VERSION ""

NS_ :

BS_:

BU_: HETC_L_ARM HMDO_1 HMAS_11 HMDO_2 HMAS_12 HMDO_3 HMAS_13 HMDO_4 HMAS_14 HMDI_5 HMAS_15

BO_ 2163243263 CTRL_HETC_L_ARM_to_ALL: 7 HETC_L_ARM
 SG_ SubCode M : 0|8@1+ (1,0) [0|0] "" HMDO_1,HMAS_11,HMDO_2,HMAS_12,HMDO_3,HMAS_13,HMDO_4,HMAS_14,HMDI_5,HMAS_15
 SG_ Rtc_Year2000 m9 : 8|8@1+ (1,0) [0|0] "" HMDO_1,HMAS_11,HMDO_2,HMAS_12,HMDO_3,HMAS_13,HMDO_4,HMAS_14,HMDI_5,HMAS_15
 SG_ Rtc_Month m9 : 16|8@1+ (1,0) [0|0] "" HMDO_1,HMAS_11,HMDO_2,HMAS_12,HMDO_3,HMAS_13,HMDO_4,HMAS_14,HMDI_5,HMAS_15
 SG_ Rtc_Day m9 : 24|8@1+ (1,0) [0|0] "" HMDO_1,HMAS_11,HMDO_2,HMAS_12,HMDO_3,HMAS_13,HMDO_4,HMAS_14,HMDI_5,HMAS_15
 SG_ Rtc_Hour m9 : 32|8@1+ (1,0) [0|0] "" HMDO_1,HMAS_11,HMDO_2,HMAS_12,HMDO_3,HMAS_13,HMDO_4,HMAS_14,HMDI_5,HMAS_15
 SG_ Rtc_Min m9 : 40|8@1+ (1,0) [0|0] "" HMDO_1,HMAS_11,HMDO_2,HMAS_12,HMDO_3,HMAS_13,HMDO_4,HMAS_14,HMDI_5,HMAS_15
 SG_ Rtc_Sec m9 : 48|8@1+ (1,0) [0|0] "" HMDO_1,HMAS_11,HMDO_2,HMAS_12,HMDO_3,HMAS_13,HMDO_4,HMAS_14,HMDI_5,HMAS_15

BO_ 2163374335 QUIET_HETC_L_ARM_to_ALL: 6 HETC_L_ARM
 SG_ Divider : 0|16@1+ (1,0) [0|0] "" HMDO_1,HMAS_11,HMDO_2,HMAS_12,HMDO_3,HMAS_13,HMDO_4,HMAS_14,HMDI_5,HMAS_15
 SG_ HoldMs : 16|32@1+ (1,0) [0|0] "ms" HMDO_1,HMAS_11,HMDO_2,HMAS_12,HMDO_3,HMAS_13,HMDO_4,HMAS_14,HMDI_5,HMAS_15

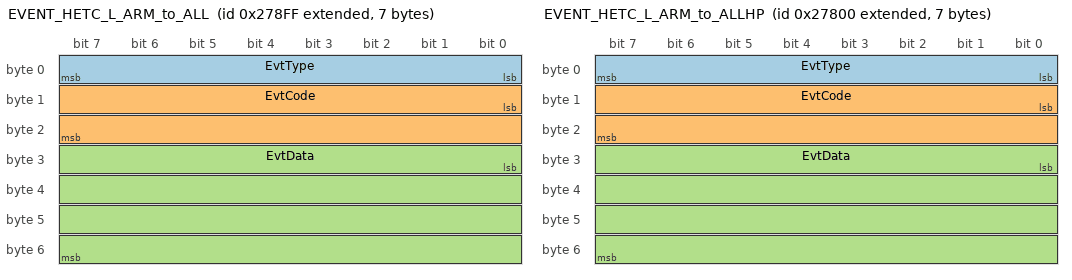
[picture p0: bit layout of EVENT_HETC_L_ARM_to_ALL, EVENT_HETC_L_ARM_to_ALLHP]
BO_ 2147645695 EVENT_HETC_L_ARM_to_ALL: 7 HETC_L_ARM
 SG_ EvtType : 0|8@1+ (1,0) [0|0] "" HMDO_1,HMAS_11,HMDO_2,HMAS_12,HMDO_3,HMAS_13,HMDO_4,HMAS_14,HMDI_5,HMAS_15
 SG_ EvtCode : 8|16@1+ (1,0) [0|0] "" HMDO_1,HMAS_11,HMDO_2,HMAS_12,HMDO_3,HMAS_13,HMDO_4,HMAS_14,HMDI_5,HMAS_15
 SG_ EvtData : 24|32@1+ (1,0) [0|0] "" HMDO_1,HMAS_11,HMDO_2,HMAS_12,HMDO_3,HMAS_13,HMDO_4,HMAS_14,HMDI_5,HMAS_15

BO_ 2147645440 EVENT_HETC_L_ARM_to_ALLHP: 7 HETC_L_ARM
 SG_ EvtType : 0|8@1+ (1,0) [0|0] "" HMDO_1,HMAS_11,HMDO_2,HMAS_12,HMDO_3,HMAS_13,HMDO_4,HMAS_14,HMDI_5,HMAS_15
 SG_ EvtCode : 8|16@1+ (1,0) [0|0] "" HMDO_1,HMAS_11,HMDO_2,HMAS_12,HMDO_3,HMAS_13,HMDO_4,HMAS_14,HMDI_5,HMAS_15
 SG_ EvtData : 24|32@1+ (1,0) [0|0] "" HMDO_1,HMAS_11,HMDO_2,HMAS_12,HMDO_3,HMAS_13,HMDO_4,HMAS_14,HMDI_5,HMAS_15

BO_ 2147710977 RPDO_HETC_L_ARM_to_HMDO_1: 16 HETC_L_ARM
 SG_ Type : 0|8@1+ (1,0) [0|0] "" HMDO_1
 SG_ ReqState : 8|8@1+ (1,0) [0|0] "" HMDO_1
 SG_ DesiredMode : 16|8@1+ (1,0) [0|0] "" HMDO_1
 SG_ DesiredPosition : 24|32@1- (1,0) [0|0] "rad" HMDO_1
 SG_ DesiredVelocity : 56|32@1- (1,0) [0|0] "rad/s" HMDO_1
 SG_ DesiredTorque : 88|32@1- (1,0) [0|0] "" HMDO_1

BO_ 2147746168 TPDO_HMDO_1_to_HETC_L_ARM: 20 HMDO_1
 SG_ Type : 0|8@1+ (1,0) [0|0] "" HETC_L_ARM
 SG_ ErrCode : 8|32@1+ (1,0) [0|0] "" HETC_L_ARM
 SG_ PresentState : 40|8@1+ (1,0) [0|0] "" HETC_L_ARM
 SG_ PresentMode : 48|8@1+ (1,0) [0|0] "" HETC_L_ARM
 SG_ PresentPosition : 56|32@1- (1,0) [0|0] "rad" HETC_L_ARM
 SG_ PresentVelocity : 88|32@1- (1,0) [0|0] "rad/s" HETC_L_ARM
 SG_ PresentTorque : 120|32@1- (1,0) [0|0] "" HETC_L_ARM
 SG_ Temperature : 152|8@1- (1,0) [0|0] "degC" HETC_L_ARM

BO_ 2163278200 STATUS_HMDO_1_to_HETC_L_ARM: 48 HMDO_1
 SG_ SubCode M : 0|8@1+ (1,0) [0|0] "" HETC_L_ARM
 SG_ Ping_CanId m5 : 8|8@1+ (1,0) [0|0] "" HETC_L_ARM
 SG_ Ping_HostId m5 : 16|8@1+ (1,0) [0|0] "" HETC_L_ARM
 SG_ Ping_Pid m5 : 24|16@1+ (1,0) [0|0] "" HETC_L_ARM
 SG_ Ping_Bid m5 : 40|16@1+ (1,0) [0|0] "" HETC_L_ARM
 SG_ Ping_Mid m5 : 56|16@1+ (1,0) [0|0] "" HETC_L_ARM
 SG_ Ping_VerMajor m5 : 72|8@1+ (1,0) [0|0] "" HETC_L_ARM
 SG_ Ping_VerMinor m5 : 80|8@1+ (1,0) [0|0] "" HETC_L_ARM
 SG_ Ping_VerPatch m5 : 88|8@1+ (1,0) [0|0] "" HETC_L_ARM
 SG_ Ping_Name0 m5 : 96|8@1+ (1,0) [0|0] "" HETC_L_ARM
 SG_ Ping_Name1 m5 : 104|8@1+ (1,0) [0|0] "" HETC_L_ARM
 SG_ Ping_Name2 m5 : 112|8@1+ (1,0) [0|0] "" HETC_L_ARM
 SG_ Ping_Name3 m5 : 120|8@1+ (1,0) [0|0] "" HETC_L_ARM
 SG_ Ping_Name4 m5 : 128|8@1+ (1,0) [0|0] "" HETC_L_ARM
 SG_ Ping_Name5 m5 : 136|8@1+ (1,0) [0|0] "" HETC_L_ARM
 SG_ Ping_Name6 m5 : 144|8@1+ (1,0) [0|0] "" HETC_L_ARM
 SG_ Ping_Name7 m5 : 152|8@1+ (1,0) [0|0] "" HETC_L_ARM
 SG_ Ping_Name8 m5 : 160|8@1+ (1,0) [0|0] "" HETC_L_ARM
 SG_ Ping_Name9 m5 : 168|8@1+ (1,0) [0|0] "" HETC_L_ARM
 SG_ Ping_Name10 m5 : 176|8@1+ (1,0) [0|0] "" HETC_L_ARM
 SG_ Ping_Name11 m5 : 184|8@1+ (1,0) [0|0] "" HETC_L_ARM
 SG_ Ping_Name12 m5 : 192|8@1+ (1,0) [0|0] "" HETC_L_ARM
 SG_ Ping_Name13 m5 : 200|8@1+ (1,0) [0|0] "" HETC_L_ARM
 SG_ Ping_Name14 m5 : 208|8@1+ (1,0) [0|0] "" HETC_L_ARM
 SG_ Ping_Name15 m5 : 216|8@1+ (1,0) [0|0] "" HETC_L_ARM
 SG_ Ping_FmtVer m5 : 224|8@1+ (1,0) [0|0] "" HETC_L_ARM
 SG_ Ping_GitRev m5 : 232|32@1+ (1,0) [0|0] "" HETC_L_ARM
 SG_ Ping_FwCrc m5 : 264|16@1+ (1,0) [0|0] "" HETC_L_ARM
 SG_ Ping_UptimeS m5 : 280|16@1+ (1,0) [0|0] "s" HETC_L_ARM

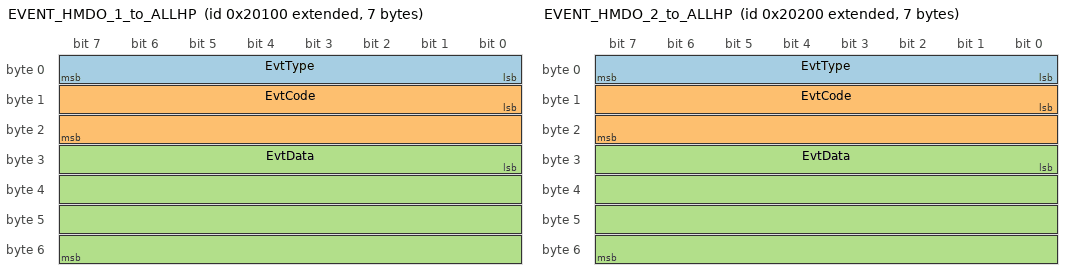
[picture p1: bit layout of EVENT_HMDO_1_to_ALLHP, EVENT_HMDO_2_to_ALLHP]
BO_ 2147614976 EVENT_HMDO_1_to_ALLHP: 7 HMDO_1
 SG_ EvtType : 0|8@1+ (1,0) [0|0] "" HETC_L_ARM,HMAS_11,HMDO_2,HMAS_12,HMDO_3,HMAS_13,HMDO_4,HMAS_14,HMDI_5,HMAS_15
 SG_ EvtCode : 8|16@1+ (1,0) [0|0] "" HETC_L_ARM,HMAS_11,HMDO_2,HMAS_12,HMDO_3,HMAS_13,HMDO_4,HMAS_14,HMDI_5,HMAS_15
 SG_ EvtData : 24|32@1+ (1,0) [0|0] "" HETC_L_ARM,HMAS_11,HMDO_2,HMAS_12,HMDO_3,HMAS_13,HMDO_4,HMAS_14,HMDI_5,HMAS_15

BO_ 2163280641 STATUS_HMAS_11_to_HMDO_1: 7 HMAS_11
 SG_ SubCode M : 0|8@1+ (1,0) [0|0] "" HMDO_1
 SG_ Ang_Ready m17 : 8|1@1+ (1,0) [0|0] "" HMDO_1
 SG_ Ang_Valid m17 : 9|1@1+ (1,0) [0|0] "" HMDO_1
 SG_ Ang_ExtErr m17 : 12|8@1+ (1,0) [0|0] "" HMDO_1
 SG_ Ang_AngleRad m17 : 24|32@1- (1,0) [0|0] "rad" HMDO_1

BO_ 2163280760 STATUS_HMAS_11_to_HETC_L_ARM: 48 HMAS_11
 SG_ SubCode M : 0|8@1+ (1,0) [0|0] "" HETC_L_ARM
 SG_ Ping_CanId m5 : 8|8@1+ (1,0) [0|0] "" HETC_L_ARM
 SG_ Ping_HostId m5 : 16|8@1+ (1,0) [0|0] "" HETC_L_ARM
 SG_ Ping_Pid m5 : 24|16@1+ (1,0) [0|0] "" HETC_L_ARM
 SG_ Ping_Bid m5 : 40|16@1+ (1,0) [0|0] "" HETC_L_ARM
 SG_ Ping_Mid m5 : 56|16@1+ (1,0) [0|0] "" HETC_L_ARM
 SG_ Ping_VerMajor m5 : 72|8@1+ (1,0) [0|0] "" HETC_L_ARM
 SG_ Ping_VerMinor m5 : 80|8@1+ (1,0) [0|0] "" HETC_L_ARM
 SG_ Ping_VerPatch m5 : 88|8@1+ (1,0) [0|0] "" HETC_L_ARM
 SG_ Ping_Name0 m5 : 96|8@1+ (1,0) [0|0] "" HETC_L_ARM
 SG_ Ping_Name1 m5 : 104|8@1+ (1,0) [0|0] "" HETC_L_ARM
 SG_ Ping_Name2 m5 : 112|8@1+ (1,0) [0|0] "" HETC_L_ARM
 SG_ Ping_Name3 m5 : 120|8@1+ (1,0) [0|0] "" HETC_L_ARM
 SG_ Ping_Name4 m5 : 128|8@1+ (1,0) [0|0] "" HETC_L_ARM
 SG_ Ping_Name5 m5 : 136|8@1+ (1,0) [0|0] "" HETC_L_ARM
 SG_ Ping_Name6 m5 : 144|8@1+ (1,0) [0|0] "" HETC_L_ARM
 SG_ Ping_Name7 m5 : 152|8@1+ (1,0) [0|0] "" HETC_L_ARM
 SG_ Ping_Name8 m5 : 160|8@1+ (1,0) [0|0] "" HETC_L_ARM
 SG_ Ping_Name9 m5 : 168|8@1+ (1,0) [0|0] "" HETC_L_ARM
 SG_ Ping_Name10 m5 : 176|8@1+ (1,0) [0|0] "" HETC_L_ARM
 SG_ Ping_Name11 m5 : 184|8@1+ (1,0) [0|0] "" HETC_L_ARM
 SG_ Ping_Name12 m5 : 192|8@1+ (1,0) [0|0] "" HETC_L_ARM
 SG_ Ping_Name13 m5 : 200|8@1+ (1,0) [0|0] "" HETC_L_ARM
 SG_ Ping_Name14 m5 : 208|8@1+ (1,0) [0|0] "" HETC_L_ARM
 SG_ Ping_Name15 m5 : 216|8@1+ (1,0) [0|0] "" HETC_L_ARM
 SG_ Ping_FmtVer m5 : 224|8@1+ (1,0) [0|0] "" HETC_L_ARM
 SG_ Ping_GitRev m5 : 232|32@1+ (1,0) [0|0] "" HETC_L_ARM
 SG_ Ping_FwCrc m5 : 264|16@1+ (1,0) [0|0] "" HETC_L_ARM
 SG_ Ping_UptimeS m5 : 280|16@1+ (1,0) [0|0] "s" HETC_L_ARM

BO_ 2147710978 RPDO_HETC_L_ARM_to_HMDO_2: 16 HETC_L_ARM
 SG_ Type : 0|8@1+ (1,0) [0|0] "" HMDO_2
 SG_ ReqState : 8|8@1+ (1,0) [0|0] "" HMDO_2
 SG_ DesiredMode : 16|8@1+ (1,0) [0|0] "" HMDO_2
 SG_ DesiredPosition : 24|32@1- (1,0) [0|0] "rad" HMDO_2
 SG_ DesiredVelocity : 56|32@1- (1,0) [0|0] "rad/s" HMDO_2
 SG_ DesiredTorque : 88|32@1- (1,0) [0|0] "" HMDO_2

BO_ 2147746424 TPDO_HMDO_2_to_HETC_L_ARM: 20 HMDO_2
 SG_ Type : 0|8@1+ (1,0) [0|0] "" HETC_L_ARM
 SG_ ErrCode : 8|32@1+ (1,0) [0|0] "" HETC_L_ARM
 SG_ PresentState : 40|8@1+ (1,0) [0|0] "" HETC_L_ARM
 SG_ PresentMode : 48|8@1+ (1,0) [0|0] "" HETC_L_ARM
 SG_ PresentPosition : 56|32@1- (1,0) [0|0] "rad" HETC_L_ARM
 SG_ PresentVelocity : 88|32@1- (1,0) [0|0] "rad/s" HETC_L_ARM
 SG_ PresentTorque : 120|32@1- (1,0) [0|0] "" HETC_L_ARM
 SG_ Temperature : 152|8@1- (1,0) [0|0] "degC" HETC_L_ARM

BO_ 2163278456 STATUS_HMDO_2_to_HETC_L_ARM: 48 HMDO_2
 SG_ SubCode M : 0|8@1+ (1,0) [0|0] "" HETC_L_ARM
 SG_ Ping_CanId m5 : 8|8@1+ (1,0) [0|0] "" HETC_L_ARM
 SG_ Ping_HostId m5 : 16|8@1+ (1,0) [0|0] "" HETC_L_ARM
 SG_ Ping_Pid m5 : 24|16@1+ (1,0) [0|0] "" HETC_L_ARM
 SG_ Ping_Bid m5 : 40|16@1+ (1,0) [0|0] "" HETC_L_ARM
 SG_ Ping_Mid m5 : 56|16@1+ (1,0) [0|0] "" HETC_L_ARM
 SG_ Ping_VerMajor m5 : 72|8@1+ (1,0) [0|0] "" HETC_L_ARM
 SG_ Ping_VerMinor m5 : 80|8@1+ (1,0) [0|0] "" HETC_L_ARM
 SG_ Ping_VerPatch m5 : 88|8@1+ (1,0) [0|0] "" HETC_L_ARM
 SG_ Ping_Name0 m5 : 96|8@1+ (1,0) [0|0] "" HETC_L_ARM
 SG_ Ping_Name1 m5 : 104|8@1+ (1,0) [0|0] "" HETC_L_ARM
 SG_ Ping_Name2 m5 : 112|8@1+ (1,0) [0|0] "" HETC_L_ARM
 SG_ Ping_Name3 m5 : 120|8@1+ (1,0) [0|0] "" HETC_L_ARM
 SG_ Ping_Name4 m5 : 128|8@1+ (1,0) [0|0] "" HETC_L_ARM
 SG_ Ping_Name5 m5 : 136|8@1+ (1,0) [0|0] "" HETC_L_ARM
 SG_ Ping_Name6 m5 : 144|8@1+ (1,0) [0|0] "" HETC_L_ARM
 SG_ Ping_Name7 m5 : 152|8@1+ (1,0) [0|0] "" HETC_L_ARM
 SG_ Ping_Name8 m5 : 160|8@1+ (1,0) [0|0] "" HETC_L_ARM
 SG_ Ping_Name9 m5 : 168|8@1+ (1,0) [0|0] "" HETC_L_ARM
 SG_ Ping_Name10 m5 : 176|8@1+ (1,0) [0|0] "" HETC_L_ARM
 SG_ Ping_Name11 m5 : 184|8@1+ (1,0) [0|0] "" HETC_L_ARM
 SG_ Ping_Name12 m5 : 192|8@1+ (1,0) [0|0] "" HETC_L_ARM
 SG_ Ping_Name13 m5 : 200|8@1+ (1,0) [0|0] "" HETC_L_ARM
 SG_ Ping_Name14 m5 : 208|8@1+ (1,0) [0|0] "" HETC_L_ARM
 SG_ Ping_Name15 m5 : 216|8@1+ (1,0) [0|0] "" HETC_L_ARM
 SG_ Ping_FmtVer m5 : 224|8@1+ (1,0) [0|0] "" HETC_L_ARM
 SG_ Ping_GitRev m5 : 232|32@1+ (1,0) [0|0] "" HETC_L_ARM
 SG_ Ping_FwCrc m5 : 264|16@1+ (1,0) [0|0] "" HETC_L_ARM
 SG_ Ping_UptimeS m5 : 280|16@1+ (1,0) [0|0] "s" HETC_L_ARM

BO_ 2147615232 EVENT_HMDO_2_to_ALLHP: 7 HMDO_2
 SG_ EvtType : 0|8@1+ (1,0) [0|0] "" HETC_L_ARM,HMDO_1,HMAS_11,HMAS_12,HMDO_3,HMAS_13,HMDO_4,HMAS_14,HMDI_5,HMAS_15
 SG_ EvtCode : 8|16@1+ (1,0) [0|0] "" HETC_L_ARM,HMDO_1,HMAS_11,HMAS_12,HMDO_3,HMAS_13,HMDO_4,HMAS_14,HMDI_5,HMAS_15
 SG_ EvtData : 24|32@1+ (1,0) [0|0] "" HETC_L_ARM,HMDO_1,HMAS_11,HMAS_12,HMDO_3,HMAS_13,HMDO_4,HMAS_14,HMDI_5,HMAS_15

BO_ 2163280898 STATUS_HMAS_12_to_HMDO_2: 7 HMAS_12
 SG_ SubCode M : 0|8@1+ (1,0) [0|0] "" HMDO_2
 SG_ Ang_Ready m17 : 8|1@1+ (1,0) [0|0] "" HMDO_2
 SG_ Ang_Valid m17 : 9|1@1+ (1,0) [0|0] "" HMDO_2
 SG_ Ang_ExtErr m17 : 12|8@1+ (1,0) [0|0] "" HMDO_2
 SG_ Ang_AngleRad m17 : 24|32@1- (1,0) [0|0] "rad" HMDO_2

BO_ 2163281016 STATUS_HMAS_12_to_HETC_L_ARM: 48 HMAS_12
 SG_ SubCode M : 0|8@1+ (1,0) [0|0] "" HETC_L_ARM
 SG_ Ping_CanId m5 : 8|8@1+ (1,0) [0|0] "" HETC_L_ARM
 SG_ Ping_HostId m5 : 16|8@1+ (1,0) [0|0] "" HETC_L_ARM
 SG_ Ping_Pid m5 : 24|16@1+ (1,0) [0|0] "" HETC_L_ARM
 SG_ Ping_Bid m5 : 40|16@1+ (1,0) [0|0] "" HETC_L_ARM
 SG_ Ping_Mid m5 : 56|16@1+ (1,0) [0|0] "" HETC_L_ARM
 SG_ Ping_VerMajor m5 : 72|8@1+ (1,0) [0|0] "" HETC_L_ARM
 SG_ Ping_VerMinor m5 : 80|8@1+ (1,0) [0|0] "" HETC_L_ARM
 SG_ Ping_VerPatch m5 : 88|8@1+ (1,0) [0|0] "" HETC_L_ARM
 SG_ Ping_Name0 m5 : 96|8@1+ (1,0) [0|0] "" HETC_L_ARM
 SG_ Ping_Name1 m5 : 104|8@1+ (1,0) [0|0] "" HETC_L_ARM
 SG_ Ping_Name2 m5 : 112|8@1+ (1,0) [0|0] "" HETC_L_ARM
 SG_ Ping_Name3 m5 : 120|8@1+ (1,0) [0|0] "" HETC_L_ARM
 SG_ Ping_Name4 m5 : 128|8@1+ (1,0) [0|0] "" HETC_L_ARM
 SG_ Ping_Name5 m5 : 136|8@1+ (1,0) [0|0] "" HETC_L_ARM
 SG_ Ping_Name6 m5 : 144|8@1+ (1,0) [0|0] "" HETC_L_ARM
 SG_ Ping_Name7 m5 : 152|8@1+ (1,0) [0|0] "" HETC_L_ARM
 SG_ Ping_Name8 m5 : 160|8@1+ (1,0) [0|0] "" HETC_L_ARM
 SG_ Ping_Name9 m5 : 168|8@1+ (1,0) [0|0] "" HETC_L_ARM
 SG_ Ping_Name10 m5 : 176|8@1+ (1,0) [0|0] "" HETC_L_ARM
 SG_ Ping_Name11 m5 : 184|8@1+ (1,0) [0|0] "" HETC_L_ARM
 SG_ Ping_Name12 m5 : 192|8@1+ (1,0) [0|0] "" HETC_L_ARM
 SG_ Ping_Name13 m5 : 200|8@1+ (1,0) [0|0] "" HETC_L_ARM
 SG_ Ping_Name14 m5 : 208|8@1+ (1,0) [0|0] "" HETC_L_ARM
 SG_ Ping_Name15 m5 : 216|8@1+ (1,0) [0|0] "" HETC_L_ARM
 SG_ Ping_FmtVer m5 : 224|8@1+ (1,0) [0|0] "" HETC_L_ARM
 SG_ Ping_GitRev m5 : 232|32@1+ (1,0) [0|0] "" HETC_L_ARM
 SG_ Ping_FwCrc m5 : 264|16@1+ (1,0) [0|0] "" HETC_L_ARM
 SG_ Ping_UptimeS m5 : 280|16@1+ (1,0) [0|0] "s" HETC_L_ARM

BO_ 2147710979 RPDO_HETC_L_ARM_to_HMDO_3: 16 HETC_L_ARM
 SG_ Type : 0|8@1+ (1,0) [0|0] "" HMDO_3
 SG_ ReqState : 8|8@1+ (1,0) [0|0] "" HMDO_3
 SG_ DesiredMode : 16|8@1+ (1,0) [0|0] "" HMDO_3
 SG_ DesiredPosition : 24|32@1- (1,0) [0|0] "rad" HMDO_3
 SG_ DesiredVelocity : 56|32@1- (1,0) [0|0] "rad/s" HMDO_3
 SG_ DesiredTorque : 88|32@1- (1,0) [0|0] "" HMDO_3

BO_ 2147746680 TPDO_HMDO_3_to_HETC_L_ARM: 20 HMDO_3
 SG_ Type : 0|8@1+ (1,0) [0|0] "" HETC_L_ARM
 SG_ ErrCode : 8|32@1+ (1,0) [0|0] "" HETC_L_ARM
 SG_ PresentState : 40|8@1+ (1,0) [0|0] "" HETC_L_ARM
 SG_ PresentMode : 48|8@1+ (1,0) [0|0] "" HETC_L_ARM
 SG_ PresentPosition : 56|32@1- (1,0) [0|0] "rad" HETC_L_ARM
 SG_ PresentVelocity : 88|32@1- (1,0) [0|0] "rad/s" HETC_L_ARM
 SG_ PresentTorque : 120|32@1- (1,0) [0|0] "" HETC_L_ARM
 SG_ Temperature : 152|8@1- (1,0) [0|0] "degC" HETC_L_ARM

BO_ 2163278712 STATUS_HMDO_3_to_HETC_L_ARM: 48 HMDO_3
 SG_ SubCode M : 0|8@1+ (1,0) [0|0] "" HETC_L_ARM
 SG_ Ping_CanId m5 : 8|8@1+ (1,0) [0|0] "" HETC_L_ARM
 SG_ Ping_HostId m5 : 16|8@1+ (1,0) [0|0] "" HETC_L_ARM
 SG_ Ping_Pid m5 : 24|16@1+ (1,0) [0|0] "" HETC_L_ARM
 SG_ Ping_Bid m5 : 40|16@1+ (1,0) [0|0] "" HETC_L_ARM
 SG_ Ping_Mid m5 : 56|16@1+ (1,0) [0|0] "" HETC_L_ARM
 SG_ Ping_VerMajor m5 : 72|8@1+ (1,0) [0|0] "" HETC_L_ARM
 SG_ Ping_VerMinor m5 : 80|8@1+ (1,0) [0|0] "" HETC_L_ARM
 SG_ Ping_VerPatch m5 : 88|8@1+ (1,0) [0|0] "" HETC_L_ARM
 SG_ Ping_Name0 m5 : 96|8@1+ (1,0) [0|0] "" HETC_L_ARM
 SG_ Ping_Name1 m5 : 104|8@1+ (1,0) [0|0] "" HETC_L_ARM
 SG_ Ping_Name2 m5 : 112|8@1+ (1,0) [0|0] "" HETC_L_ARM
 SG_ Ping_Name3 m5 : 120|8@1+ (1,0) [0|0] "" HETC_L_ARM
 SG_ Ping_Name4 m5 : 128|8@1+ (1,0) [0|0] "" HETC_L_ARM
 SG_ Ping_Name5 m5 : 136|8@1+ (1,0) [0|0] "" HETC_L_ARM
 SG_ Ping_Name6 m5 : 144|8@1+ (1,0) [0|0] "" HETC_L_ARM
 SG_ Ping_Name7 m5 : 152|8@1+ (1,0) [0|0] "" HETC_L_ARM
 SG_ Ping_Name8 m5 : 160|8@1+ (1,0) [0|0] "" HETC_L_ARM
 SG_ Ping_Name9 m5 : 168|8@1+ (1,0) [0|0] "" HETC_L_ARM
 SG_ Ping_Name10 m5 : 176|8@1+ (1,0) [0|0] "" HETC_L_ARM
 SG_ Ping_Name11 m5 : 184|8@1+ (1,0) [0|0] "" HETC_L_ARM
 SG_ Ping_Name12 m5 : 192|8@1+ (1,0) [0|0] "" HETC_L_ARM
 SG_ Ping_Name13 m5 : 200|8@1+ (1,0) [0|0] "" HETC_L_ARM
 SG_ Ping_Name14 m5 : 208|8@1+ (1,0) [0|0] "" HETC_L_ARM
 SG_ Ping_Name15 m5 : 216|8@1+ (1,0) [0|0] "" HETC_L_ARM
 SG_ Ping_FmtVer m5 : 224|8@1+ (1,0) [0|0] "" HETC_L_ARM
 SG_ Ping_GitRev m5 : 232|32@1+ (1,0) [0|0] "" HETC_L_ARM
 SG_ Ping_FwCrc m5 : 264|16@1+ (1,0) [0|0] "" HETC_L_ARM
 SG_ Ping_UptimeS m5 : 280|16@1+ (1,0) [0|0] "s" HETC_L_ARM

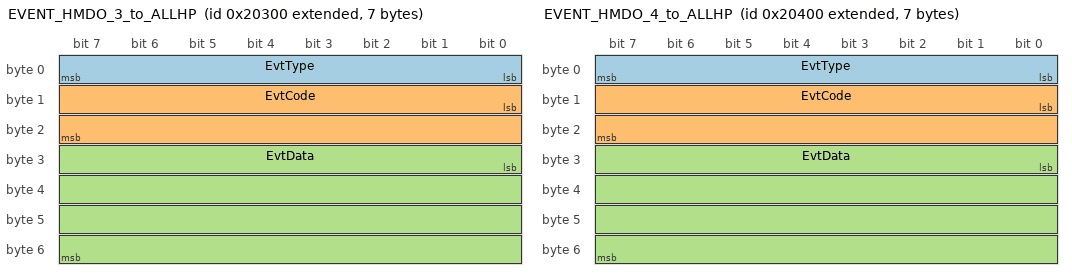
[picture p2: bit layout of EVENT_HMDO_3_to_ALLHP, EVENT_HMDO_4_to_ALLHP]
BO_ 2147615488 EVENT_HMDO_3_to_ALLHP: 7 HMDO_3
 SG_ EvtType : 0|8@1+ (1,0) [0|0] "" HETC_L_ARM,HMDO_1,HMAS_11,HMDO_2,HMAS_12,HMAS_13,HMDO_4,HMAS_14,HMDI_5,HMAS_15
 SG_ EvtCode : 8|16@1+ (1,0) [0|0] "" HETC_L_ARM,HMDO_1,HMAS_11,HMDO_2,HMAS_12,HMAS_13,HMDO_4,HMAS_14,HMDI_5,HMAS_15
 SG_ EvtData : 24|32@1+ (1,0) [0|0] "" HETC_L_ARM,HMDO_1,HMAS_11,HMDO_2,HMAS_12,HMAS_13,HMDO_4,HMAS_14,HMDI_5,HMAS_15

BO_ 2163281155 STATUS_HMAS_13_to_HMDO_3: 7 HMAS_13
 SG_ SubCode M : 0|8@1+ (1,0) [0|0] "" HMDO_3
 SG_ Ang_Ready m17 : 8|1@1+ (1,0) [0|0] "" HMDO_3
 SG_ Ang_Valid m17 : 9|1@1+ (1,0) [0|0] "" HMDO_3
 SG_ Ang_ExtErr m17 : 12|8@1+ (1,0) [0|0] "" HMDO_3
 SG_ Ang_AngleRad m17 : 24|32@1- (1,0) [0|0] "rad" HMDO_3

BO_ 2163281272 STATUS_HMAS_13_to_HETC_L_ARM: 48 HMAS_13
 SG_ SubCode M : 0|8@1+ (1,0) [0|0] "" HETC_L_ARM
 SG_ Ping_CanId m5 : 8|8@1+ (1,0) [0|0] "" HETC_L_ARM
 SG_ Ping_HostId m5 : 16|8@1+ (1,0) [0|0] "" HETC_L_ARM
 SG_ Ping_Pid m5 : 24|16@1+ (1,0) [0|0] "" HETC_L_ARM
 SG_ Ping_Bid m5 : 40|16@1+ (1,0) [0|0] "" HETC_L_ARM
 SG_ Ping_Mid m5 : 56|16@1+ (1,0) [0|0] "" HETC_L_ARM
 SG_ Ping_VerMajor m5 : 72|8@1+ (1,0) [0|0] "" HETC_L_ARM
 SG_ Ping_VerMinor m5 : 80|8@1+ (1,0) [0|0] "" HETC_L_ARM
 SG_ Ping_VerPatch m5 : 88|8@1+ (1,0) [0|0] "" HETC_L_ARM
 SG_ Ping_Name0 m5 : 96|8@1+ (1,0) [0|0] "" HETC_L_ARM
 SG_ Ping_Name1 m5 : 104|8@1+ (1,0) [0|0] "" HETC_L_ARM
 SG_ Ping_Name2 m5 : 112|8@1+ (1,0) [0|0] "" HETC_L_ARM
 SG_ Ping_Name3 m5 : 120|8@1+ (1,0) [0|0] "" HETC_L_ARM
 SG_ Ping_Name4 m5 : 128|8@1+ (1,0) [0|0] "" HETC_L_ARM
 SG_ Ping_Name5 m5 : 136|8@1+ (1,0) [0|0] "" HETC_L_ARM
 SG_ Ping_Name6 m5 : 144|8@1+ (1,0) [0|0] "" HETC_L_ARM
 SG_ Ping_Name7 m5 : 152|8@1+ (1,0) [0|0] "" HETC_L_ARM
 SG_ Ping_Name8 m5 : 160|8@1+ (1,0) [0|0] "" HETC_L_ARM
 SG_ Ping_Name9 m5 : 168|8@1+ (1,0) [0|0] "" HETC_L_ARM
 SG_ Ping_Name10 m5 : 176|8@1+ (1,0) [0|0] "" HETC_L_ARM
 SG_ Ping_Name11 m5 : 184|8@1+ (1,0) [0|0] "" HETC_L_ARM
 SG_ Ping_Name12 m5 : 192|8@1+ (1,0) [0|0] "" HETC_L_ARM
 SG_ Ping_Name13 m5 : 200|8@1+ (1,0) [0|0] "" HETC_L_ARM
 SG_ Ping_Name14 m5 : 208|8@1+ (1,0) [0|0] "" HETC_L_ARM
 SG_ Ping_Name15 m5 : 216|8@1+ (1,0) [0|0] "" HETC_L_ARM
 SG_ Ping_FmtVer m5 : 224|8@1+ (1,0) [0|0] "" HETC_L_ARM
 SG_ Ping_GitRev m5 : 232|32@1+ (1,0) [0|0] "" HETC_L_ARM
 SG_ Ping_FwCrc m5 : 264|16@1+ (1,0) [0|0] "" HETC_L_ARM
 SG_ Ping_UptimeS m5 : 280|16@1+ (1,0) [0|0] "s" HETC_L_ARM

BO_ 2147710980 RPDO_HETC_L_ARM_to_HMDO_4: 16 HETC_L_ARM
 SG_ Type : 0|8@1+ (1,0) [0|0] "" HMDO_4
 SG_ ReqState : 8|8@1+ (1,0) [0|0] "" HMDO_4
 SG_ DesiredMode : 16|8@1+ (1,0) [0|0] "" HMDO_4
 SG_ DesiredPosition : 24|32@1- (1,0) [0|0] "rad" HMDO_4
 SG_ DesiredVelocity : 56|32@1- (1,0) [0|0] "rad/s" HMDO_4
 SG_ DesiredTorque : 88|32@1- (1,0) [0|0] "" HMDO_4

BO_ 2147746936 TPDO_HMDO_4_to_HETC_L_ARM: 20 HMDO_4
 SG_ Type : 0|8@1+ (1,0) [0|0] "" HETC_L_ARM
 SG_ ErrCode : 8|32@1+ (1,0) [0|0] "" HETC_L_ARM
 SG_ PresentState : 40|8@1+ (1,0) [0|0] "" HETC_L_ARM
 SG_ PresentMode : 48|8@1+ (1,0) [0|0] "" HETC_L_ARM
 SG_ PresentPosition : 56|32@1- (1,0) [0|0] "rad" HETC_L_ARM
 SG_ PresentVelocity : 88|32@1- (1,0) [0|0] "rad/s" HETC_L_ARM
 SG_ PresentTorque : 120|32@1- (1,0) [0|0] "" HETC_L_ARM
 SG_ Temperature : 152|8@1- (1,0) [0|0] "degC" HETC_L_ARM

BO_ 2163278968 STATUS_HMDO_4_to_HETC_L_ARM: 48 HMDO_4
 SG_ SubCode M : 0|8@1+ (1,0) [0|0] "" HETC_L_ARM
 SG_ Ping_CanId m5 : 8|8@1+ (1,0) [0|0] "" HETC_L_ARM
 SG_ Ping_HostId m5 : 16|8@1+ (1,0) [0|0] "" HETC_L_ARM
 SG_ Ping_Pid m5 : 24|16@1+ (1,0) [0|0] "" HETC_L_ARM
 SG_ Ping_Bid m5 : 40|16@1+ (1,0) [0|0] "" HETC_L_ARM
 SG_ Ping_Mid m5 : 56|16@1+ (1,0) [0|0] "" HETC_L_ARM
 SG_ Ping_VerMajor m5 : 72|8@1+ (1,0) [0|0] "" HETC_L_ARM
 SG_ Ping_VerMinor m5 : 80|8@1+ (1,0) [0|0] "" HETC_L_ARM
 SG_ Ping_VerPatch m5 : 88|8@1+ (1,0) [0|0] "" HETC_L_ARM
 SG_ Ping_Name0 m5 : 96|8@1+ (1,0) [0|0] "" HETC_L_ARM
 SG_ Ping_Name1 m5 : 104|8@1+ (1,0) [0|0] "" HETC_L_ARM
 SG_ Ping_Name2 m5 : 112|8@1+ (1,0) [0|0] "" HETC_L_ARM
 SG_ Ping_Name3 m5 : 120|8@1+ (1,0) [0|0] "" HETC_L_ARM
 SG_ Ping_Name4 m5 : 128|8@1+ (1,0) [0|0] "" HETC_L_ARM
 SG_ Ping_Name5 m5 : 136|8@1+ (1,0) [0|0] "" HETC_L_ARM
 SG_ Ping_Name6 m5 : 144|8@1+ (1,0) [0|0] "" HETC_L_ARM
 SG_ Ping_Name7 m5 : 152|8@1+ (1,0) [0|0] "" HETC_L_ARM
 SG_ Ping_Name8 m5 : 160|8@1+ (1,0) [0|0] "" HETC_L_ARM
 SG_ Ping_Name9 m5 : 168|8@1+ (1,0) [0|0] "" HETC_L_ARM
 SG_ Ping_Name10 m5 : 176|8@1+ (1,0) [0|0] "" HETC_L_ARM
 SG_ Ping_Name11 m5 : 184|8@1+ (1,0) [0|0] "" HETC_L_ARM
 SG_ Ping_Name12 m5 : 192|8@1+ (1,0) [0|0] "" HETC_L_ARM
 SG_ Ping_Name13 m5 : 200|8@1+ (1,0) [0|0] "" HETC_L_ARM
 SG_ Ping_Name14 m5 : 208|8@1+ (1,0) [0|0] "" HETC_L_ARM
 SG_ Ping_Name15 m5 : 216|8@1+ (1,0) [0|0] "" HETC_L_ARM
 SG_ Ping_FmtVer m5 : 224|8@1+ (1,0) [0|0] "" HETC_L_ARM
 SG_ Ping_GitRev m5 : 232|32@1+ (1,0) [0|0] "" HETC_L_ARM
 SG_ Ping_FwCrc m5 : 264|16@1+ (1,0) [0|0] "" HETC_L_ARM
 SG_ Ping_UptimeS m5 : 280|16@1+ (1,0) [0|0] "s" HETC_L_ARM

BO_ 2147615744 EVENT_HMDO_4_to_ALLHP: 7 HMDO_4
 SG_ EvtType : 0|8@1+ (1,0) [0|0] "" HETC_L_ARM,HMDO_1,HMAS_11,HMDO_2,HMAS_12,HMDO_3,HMAS_13,HMAS_14,HMDI_5,HMAS_15
 SG_ EvtCode : 8|16@1+ (1,0) [0|0] "" HETC_L_ARM,HMDO_1,HMAS_11,HMDO_2,HMAS_12,HMDO_3,HMAS_13,HMAS_14,HMDI_5,HMAS_15
 SG_ EvtData : 24|32@1+ (1,0) [0|0] "" HETC_L_ARM,HMDO_1,HMAS_11,HMDO_2,HMAS_12,HMDO_3,HMAS_13,HMAS_14,HMDI_5,HMAS_15

BO_ 2163281412 STATUS_HMAS_14_to_HMDO_4: 7 HMAS_14
 SG_ SubCode M : 0|8@1+ (1,0) [0|0] "" HMDO_4
 SG_ Ang_Ready m17 : 8|1@1+ (1,0) [0|0] "" HMDO_4
 SG_ Ang_Valid m17 : 9|1@1+ (1,0) [0|0] "" HMDO_4
 SG_ Ang_ExtErr m17 : 12|8@1+ (1,0) [0|0] "" HMDO_4
 SG_ Ang_AngleRad m17 : 24|32@1- (1,0) [0|0] "rad" HMDO_4

BO_ 2163281528 STATUS_HMAS_14_to_HETC_L_ARM: 48 HMAS_14
 SG_ SubCode M : 0|8@1+ (1,0) [0|0] "" HETC_L_ARM
 SG_ Ping_CanId m5 : 8|8@1+ (1,0) [0|0] "" HETC_L_ARM
 SG_ Ping_HostId m5 : 16|8@1+ (1,0) [0|0] "" HETC_L_ARM
 SG_ Ping_Pid m5 : 24|16@1+ (1,0) [0|0] "" HETC_L_ARM
 SG_ Ping_Bid m5 : 40|16@1+ (1,0) [0|0] "" HETC_L_ARM
 SG_ Ping_Mid m5 : 56|16@1+ (1,0) [0|0] "" HETC_L_ARM
 SG_ Ping_VerMajor m5 : 72|8@1+ (1,0) [0|0] "" HETC_L_ARM
 SG_ Ping_VerMinor m5 : 80|8@1+ (1,0) [0|0] "" HETC_L_ARM
 SG_ Ping_VerPatch m5 : 88|8@1+ (1,0) [0|0] "" HETC_L_ARM
 SG_ Ping_Name0 m5 : 96|8@1+ (1,0) [0|0] "" HETC_L_ARM
 SG_ Ping_Name1 m5 : 104|8@1+ (1,0) [0|0] "" HETC_L_ARM
 SG_ Ping_Name2 m5 : 112|8@1+ (1,0) [0|0] "" HETC_L_ARM
 SG_ Ping_Name3 m5 : 120|8@1+ (1,0) [0|0] "" HETC_L_ARM
 SG_ Ping_Name4 m5 : 128|8@1+ (1,0) [0|0] "" HETC_L_ARM
 SG_ Ping_Name5 m5 : 136|8@1+ (1,0) [0|0] "" HETC_L_ARM
 SG_ Ping_Name6 m5 : 144|8@1+ (1,0) [0|0] "" HETC_L_ARM
 SG_ Ping_Name7 m5 : 152|8@1+ (1,0) [0|0] "" HETC_L_ARM
 SG_ Ping_Name8 m5 : 160|8@1+ (1,0) [0|0] "" HETC_L_ARM
 SG_ Ping_Name9 m5 : 168|8@1+ (1,0) [0|0] "" HETC_L_ARM
 SG_ Ping_Name10 m5 : 176|8@1+ (1,0) [0|0] "" HETC_L_ARM
 SG_ Ping_Name11 m5 : 184|8@1+ (1,0) [0|0] "" HETC_L_ARM
 SG_ Ping_Name12 m5 : 192|8@1+ (1,0) [0|0] "" HETC_L_ARM
 SG_ Ping_Name13 m5 : 200|8@1+ (1,0) [0|0] "" HETC_L_ARM
 SG_ Ping_Name14 m5 : 208|8@1+ (1,0) [0|0] "" HETC_L_ARM
 SG_ Ping_Name15 m5 : 216|8@1+ (1,0) [0|0] "" HETC_L_ARM
 SG_ Ping_FmtVer m5 : 224|8@1+ (1,0) [0|0] "" HETC_L_ARM
 SG_ Ping_GitRev m5 : 232|32@1+ (1,0) [0|0] "" HETC_L_ARM
 SG_ Ping_FwCrc m5 : 264|16@1+ (1,0) [0|0] "" HETC_L_ARM
 SG_ Ping_UptimeS m5 : 280|16@1+ (1,0) [0|0] "s" HETC_L_ARM

BO_ 2147710981 RPDO_HETC_L_ARM_to_HMDI_5: 16 HETC_L_ARM
 SG_ Type : 0|8@1+ (1,0) [0|0] "" HMDI_5
 SG_ ReqState : 8|8@1+ (1,0) [0|0] "" HMDI_5
 SG_ DesiredMode : 16|8@1+ (1,0) [0|0] "" HMDI_5
 SG_ DesiredPosition : 24|32@1- (1,0) [0|0] "rad" HMDI_5
 SG_ DesiredVelocity : 56|32@1- (1,0) [0|0] "rad/s" HMDI_5
 SG_ DesiredTorque : 88|32@1- (1,0) [0|0] "" HMDI_5

BO_ 2147747192 TPDO_HMDI_5_to_HETC_L_ARM: 20 HMDI_5
 SG_ Type : 0|8@1+ (1,0) [0|0] "" HETC_L_ARM
 SG_ ErrCode : 8|32@1+ (1,0) [0|0] "" HETC_L_ARM
 SG_ PresentState : 40|8@1+ (1,0) [0|0] "" HETC_L_ARM
 SG_ PresentMode : 48|8@1+ (1,0) [0|0] "" HETC_L_ARM
 SG_ PresentPosition : 56|32@1- (1,0) [0|0] "rad" HETC_L_ARM
 SG_ PresentVelocity : 88|32@1- (1,0) [0|0] "rad/s" HETC_L_ARM
 SG_ PresentTorque : 120|32@1- (1,0) [0|0] "" HETC_L_ARM
 SG_ Temperature : 152|8@1- (1,0) [0|0] "degC" HETC_L_ARM

BO_ 2163279224 STATUS_HMDI_5_to_HETC_L_ARM: 48 HMDI_5
 SG_ SubCode M : 0|8@1+ (1,0) [0|0] "" HETC_L_ARM
 SG_ Ping_CanId m5 : 8|8@1+ (1,0) [0|0] "" HETC_L_ARM
 SG_ Ping_HostId m5 : 16|8@1+ (1,0) [0|0] "" HETC_L_ARM
 SG_ Ping_Pid m5 : 24|16@1+ (1,0) [0|0] "" HETC_L_ARM
 SG_ Ping_Bid m5 : 40|16@1+ (1,0) [0|0] "" HETC_L_ARM
 SG_ Ping_Mid m5 : 56|16@1+ (1,0) [0|0] "" HETC_L_ARM
 SG_ Ping_VerMajor m5 : 72|8@1+ (1,0) [0|0] "" HETC_L_ARM
 SG_ Ping_VerMinor m5 : 80|8@1+ (1,0) [0|0] "" HETC_L_ARM
 SG_ Ping_VerPatch m5 : 88|8@1+ (1,0) [0|0] "" HETC_L_ARM
 SG_ Ping_Name0 m5 : 96|8@1+ (1,0) [0|0] "" HETC_L_ARM
 SG_ Ping_Name1 m5 : 104|8@1+ (1,0) [0|0] "" HETC_L_ARM
 SG_ Ping_Name2 m5 : 112|8@1+ (1,0) [0|0] "" HETC_L_ARM
 SG_ Ping_Name3 m5 : 120|8@1+ (1,0) [0|0] "" HETC_L_ARM
 SG_ Ping_Name4 m5 : 128|8@1+ (1,0) [0|0] "" HETC_L_ARM
 SG_ Ping_Name5 m5 : 136|8@1+ (1,0) [0|0] "" HETC_L_ARM
 SG_ Ping_Name6 m5 : 144|8@1+ (1,0) [0|0] "" HETC_L_ARM
 SG_ Ping_Name7 m5 : 152|8@1+ (1,0) [0|0] "" HETC_L_ARM
 SG_ Ping_Name8 m5 : 160|8@1+ (1,0) [0|0] "" HETC_L_ARM
 SG_ Ping_Name9 m5 : 168|8@1+ (1,0) [0|0] "" HETC_L_ARM
 SG_ Ping_Name10 m5 : 176|8@1+ (1,0) [0|0] "" HETC_L_ARM
 SG_ Ping_Name11 m5 : 184|8@1+ (1,0) [0|0] "" HETC_L_ARM
 SG_ Ping_Name12 m5 : 192|8@1+ (1,0) [0|0] "" HETC_L_ARM
 SG_ Ping_Name13 m5 : 200|8@1+ (1,0) [0|0] "" HETC_L_ARM
 SG_ Ping_Name14 m5 : 208|8@1+ (1,0) [0|0] "" HETC_L_ARM
 SG_ Ping_Name15 m5 : 216|8@1+ (1,0) [0|0] "" HETC_L_ARM
 SG_ Ping_FmtVer m5 : 224|8@1+ (1,0) [0|0] "" HETC_L_ARM
 SG_ Ping_GitRev m5 : 232|32@1+ (1,0) [0|0] "" HETC_L_ARM
 SG_ Ping_FwCrc m5 : 264|16@1+ (1,0) [0|0] "" HETC_L_ARM
 SG_ Ping_UptimeS m5 : 280|16@1+ (1,0) [0|0] "s" HETC_L_ARM

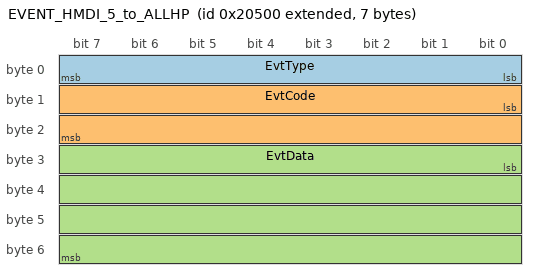
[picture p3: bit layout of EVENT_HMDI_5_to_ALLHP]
BO_ 2147616000 EVENT_HMDI_5_to_ALLHP: 7 HMDI_5
 SG_ EvtType : 0|8@1+ (1,0) [0|0] "" HETC_L_ARM,HMDO_1,HMAS_11,HMDO_2,HMAS_12,HMDO_3,HMAS_13,HMDO_4,HMAS_14,HMAS_15
 SG_ EvtCode : 8|16@1+ (1,0) [0|0] "" HETC_L_ARM,HMDO_1,HMAS_11,HMDO_2,HMAS_12,HMDO_3,HMAS_13,HMDO_4,HMAS_14,HMAS_15
 SG_ EvtData : 24|32@1+ (1,0) [0|0] "" HETC_L_ARM,HMDO_1,HMAS_11,HMDO_2,HMAS_12,HMDO_3,HMAS_13,HMDO_4,HMAS_14,HMAS_15

BO_ 2163281669 STATUS_HMAS_15_to_HMDI_5: 7 HMAS_15
 SG_ SubCode M : 0|8@1+ (1,0) [0|0] "" HMDI_5
 SG_ Ang_Ready m17 : 8|1@1+ (1,0) [0|0] "" HMDI_5
 SG_ Ang_Valid m17 : 9|1@1+ (1,0) [0|0] "" HMDI_5
 SG_ Ang_ExtErr m17 : 12|8@1+ (1,0) [0|0] "" HMDI_5
 SG_ Ang_AngleRad m17 : 24|32@1- (1,0) [0|0] "rad" HMDI_5

BO_ 2163281784 STATUS_HMAS_15_to_HETC_L_ARM: 48 HMAS_15
 SG_ SubCode M : 0|8@1+ (1,0) [0|0] "" HETC_L_ARM
 SG_ Ping_CanId m5 : 8|8@1+ (1,0) [0|0] "" HETC_L_ARM
 SG_ Ping_HostId m5 : 16|8@1+ (1,0) [0|0] "" HETC_L_ARM
 SG_ Ping_Pid m5 : 24|16@1+ (1,0) [0|0] "" HETC_L_ARM
 SG_ Ping_Bid m5 : 40|16@1+ (1,0) [0|0] "" HETC_L_ARM
 SG_ Ping_Mid m5 : 56|16@1+ (1,0) [0|0] "" HETC_L_ARM
 SG_ Ping_VerMajor m5 : 72|8@1+ (1,0) [0|0] "" HETC_L_ARM
 SG_ Ping_VerMinor m5 : 80|8@1+ (1,0) [0|0] "" HETC_L_ARM
 SG_ Ping_VerPatch m5 : 88|8@1+ (1,0) [0|0] "" HETC_L_ARM
 SG_ Ping_Name0 m5 : 96|8@1+ (1,0) [0|0] "" HETC_L_ARM
 SG_ Ping_Name1 m5 : 104|8@1+ (1,0) [0|0] "" HETC_L_ARM
 SG_ Ping_Name2 m5 : 112|8@1+ (1,0) [0|0] "" HETC_L_ARM
 SG_ Ping_Name3 m5 : 120|8@1+ (1,0) [0|0] "" HETC_L_ARM
 SG_ Ping_Name4 m5 : 128|8@1+ (1,0) [0|0] "" HETC_L_ARM
 SG_ Ping_Name5 m5 : 136|8@1+ (1,0) [0|0] "" HETC_L_ARM
 SG_ Ping_Name6 m5 : 144|8@1+ (1,0) [0|0] "" HETC_L_ARM
 SG_ Ping_Name7 m5 : 152|8@1+ (1,0) [0|0] "" HETC_L_ARM
 SG_ Ping_Name8 m5 : 160|8@1+ (1,0) [0|0] "" HETC_L_ARM
 SG_ Ping_Name9 m5 : 168|8@1+ (1,0) [0|0] "" HETC_L_ARM
 SG_ Ping_Name10 m5 : 176|8@1+ (1,0) [0|0] "" HETC_L_ARM
 SG_ Ping_Name11 m5 : 184|8@1+ (1,0) [0|0] "" HETC_L_ARM
 SG_ Ping_Name12 m5 : 192|8@1+ (1,0) [0|0] "" HETC_L_ARM
 SG_ Ping_Name13 m5 : 200|8@1+ (1,0) [0|0] "" HETC_L_ARM
 SG_ Ping_Name14 m5 : 208|8@1+ (1,0) [0|0] "" HETC_L_ARM
 SG_ Ping_Name15 m5 : 216|8@1+ (1,0) [0|0] "" HETC_L_ARM
 SG_ Ping_FmtVer m5 : 224|8@1+ (1,0) [0|0] "" HETC_L_ARM
 SG_ Ping_GitRev m5 : 232|32@1+ (1,0) [0|0] "" HETC_L_ARM
 SG_ Ping_FwCrc m5 : 264|16@1+ (1,0) [0|0] "" HETC_L_ARM
 SG_ Ping_UptimeS m5 : 280|16@1+ (1,0) [0|0] "s" HETC_L_ARM

CM_ "FM26C HETC-L-ARM_ch0. CAN ID = type<<16 | sender<<8 | dest. Generated from friday-firmware-2.0 dev c0ace19f. Design values, not measured.";
CM_ BO_ 2163243263 "CLI ping / RTC sync on all channels";
CM_ BO_ 2163374335 "slow down periodic TX, e.g. during firmware download";
CM_ BO_ 2147645695 "EVENT_ERR_CLEAR fault-reset fan-out";
CM_ BO_ 2163278200 "ping response";
CM_ BO_ 2163280641 "joint angle; dest = pair motor (hwinfo host-id)";
CM_ BO_ 2163280760 "ping response";
CM_ BO_ 2163278456 "ping response";
CM_ BO_ 2163280898 "joint angle; dest = pair motor (hwinfo host-id)";
CM_ BO_ 2163281016 "ping response";
CM_ BO_ 2163278712 "ping response";
CM_ BO_ 2163281155 "joint angle; dest = pair motor (hwinfo host-id)";
CM_ BO_ 2163281272 "ping response";
CM_ BO_ 2163278968 "ping response";
CM_ BO_ 2163281412 "joint angle; dest = pair motor (hwinfo host-id)";
CM_ BO_ 2163281528 "ping response";
CM_ BO_ 2163279224 "ping response";
CM_ BO_ 2163281669 "joint angle; dest = pair motor (hwinfo host-id)";
CM_ BO_ 2163281784 "ping response";
BA_DEF_ "DBName" STRING ;
BA_DEF_ "BusType" STRING ;
BA_DEF_ "Baudrate" INT 0 8000000;
BA_DEF_ "BaudRateCANFD" INT 0 16000000;
BA_DEF_ BO_ "GenMsgCycleTime" INT 0 65535;
BA_DEF_ BO_ "VFrameFormat" ENUM "StandardCAN","ExtendedCAN","reserved","reserved","reserved","reserved","reserved","reserved","reserved","reserved","reserved","reserved","reserved","reserved","StandardCAN_FD","ExtendedCAN_FD";
BA_DEF_ BO_ "CANFD_BRS" ENUM "0","1";
BA_DEF_ BO_ "SubCodeCycles" STRING ;
BA_DEF_ BO_ "SubCodeLengths" STRING ;
BA_DEF_DEF_ "DBName" "";
BA_DEF_DEF_ "BusType" "CAN FD";
BA_DEF_DEF_ "Baudrate" 1000000;
BA_DEF_DEF_ "BaudRateCANFD" 5000000;
BA_DEF_DEF_ "GenMsgCycleTime" 0;
BA_DEF_DEF_ "VFrameFormat" "ExtendedCAN_FD";
BA_DEF_DEF_ "CANFD_BRS" "1";
BA_DEF_DEF_ "SubCodeCycles" "";
BA_DEF_DEF_ "SubCodeLengths" "";
BA_ "DBName" "HETC_L_ARM_ch0";
BA_ "SubCodeLengths" BO_ 2163243263 "2:1;9:7";
BA_ "GenMsgCycleTime" BO_ 2147710977 2;
BA_ "GenMsgCycleTime" BO_ 2147746168 2;
BA_ "SubCodeLengths" BO_ 2163278200 "5:37";
BA_ "GenMsgCycleTime" BO_ 2163280641 2;
BA_ "SubCodeCycles" BO_ 2163280641 "17:2";
BA_ "SubCodeLengths" BO_ 2163280641 "17:7";
BA_ "SubCodeLengths" BO_ 2163280760 "5:37";
BA_ "GenMsgCycleTime" BO_ 2147710978 2;
BA_ "GenMsgCycleTime" BO_ 2147746424 2;
BA_ "SubCodeLengths" BO_ 2163278456 "5:37";
BA_ "GenMsgCycleTime" BO_ 2163280898 2;
BA_ "SubCodeCycles" BO_ 2163280898 "17:2";
BA_ "SubCodeLengths" BO_ 2163280898 "17:7";
BA_ "SubCodeLengths" BO_ 2163281016 "5:37";
BA_ "GenMsgCycleTime" BO_ 2147710979 2;
BA_ "GenMsgCycleTime" BO_ 2147746680 2;
BA_ "SubCodeLengths" BO_ 2163278712 "5:37";
BA_ "GenMsgCycleTime" BO_ 2163281155 2;
BA_ "SubCodeCycles" BO_ 2163281155 "17:2";
BA_ "SubCodeLengths" BO_ 2163281155 "17:7";
BA_ "SubCodeLengths" BO_ 2163281272 "5:37";
BA_ "GenMsgCycleTime" BO_ 2147710980 2;
BA_ "GenMsgCycleTime" BO_ 2147746936 2;
BA_ "SubCodeLengths" BO_ 2163278968 "5:37";
BA_ "GenMsgCycleTime" BO_ 2163281412 2;
BA_ "SubCodeCycles" BO_ 2163281412 "17:2";
BA_ "SubCodeLengths" BO_ 2163281412 "17:7";
BA_ "SubCodeLengths" BO_ 2163281528 "5:37";
BA_ "GenMsgCycleTime" BO_ 2147710981 2;
BA_ "GenMsgCycleTime" BO_ 2147747192 2;
BA_ "SubCodeLengths" BO_ 2163279224 "5:37";
BA_ "GenMsgCycleTime" BO_ 2163281669 2;
BA_ "SubCodeCycles" BO_ 2163281669 "17:2";
BA_ "SubCodeLengths" BO_ 2163281669 "17:7";
BA_ "SubCodeLengths" BO_ 2163281784 "5:37";
VAL_ 2163243263 SubCode 11 "POWER" 10 "THOR" 9 "RTC_SYNC" 8 "SAFETY_RESET" 7 "SAFETY_PING" 6 "ECAT_PING" 5 "BAT_LATCH" 4 "BUZZER" 3 "BRAKE" 2 "PING" 1 "MC_TARGET" 0 "MC_TORQUE" ;
VAL_ 2147645695 EvtCode 19 "CAN_ID_CHANGED" 18 "THOR_OFF" 17 "ROBOT_OFF" 16 "BLACKBOX_TRIG" 15 "BAT_WARN" 14 "ESTOP_UPDATE" 13 "ERR_CLEAR" 12 "ERR_CODE" 11 "WIZ_PHY_SNTP" 10 "WIZ_PHY_DHCP" 9 "WIZ_PHY_LINK" 8 "PAUSE" 7 "ECAT_CONNECT" 6 "ANGLE_EX_CONNECT" 5 "BRAKE_EX_CONNECT" 4 "BLDC_FAULT" 3 "BLDC_TORQUE" 2 "BLDC_LIMIT" 1 "ESTOP" 0 "OK" ;
VAL_ 2147645440 EvtCode 19 "CAN_ID_CHANGED" 18 "THOR_OFF" 17 "ROBOT_OFF" 16 "BLACKBOX_TRIG" 15 "BAT_WARN" 14 "ESTOP_UPDATE" 13 "ERR_CLEAR" 12 "ERR_CODE" 11 "WIZ_PHY_SNTP" 10 "WIZ_PHY_DHCP" 9 "WIZ_PHY_LINK" 8 "PAUSE" 7 "ECAT_CONNECT" 6 "ANGLE_EX_CONNECT" 5 "BRAKE_EX_CONNECT" 4 "BLDC_FAULT" 3 "BLDC_TORQUE" 2 "BLDC_LIMIT" 1 "ESTOP" 0 "OK" ;
VAL_ 2147710977 ReqState 240 "FAULT_RESET" 10 "QC" 9 "ESTOP" 8 "ERROR" 7 "ERR_OCCUR" 6 "PROC_OFF" 5 "RUN" 4 "TORQUE_ON" 3 "PROC_ON" 2 "READY" 1 "DISABLED" 0 "INIT" ;
VAL_ 2147710977 DesiredMode 5 "TORQUE" 4 "WHEEL" 3 "SIMPLE" 2 "POSITION" 1 "VELOCITY" 0 "IDLE" ;
VAL_ 2147746168 PresentState 10 "QC" 9 "ESTOP" 8 "ERROR" 7 "ERR_OCCUR" 6 "PROC_OFF" 5 "RUN" 4 "TORQUE_ON" 3 "PROC_ON" 2 "READY" 1 "DISABLED" 0 "INIT" ;
VAL_ 2147746168 PresentMode 5 "TORQUE" 4 "WHEEL" 3 "SIMPLE" 2 "POSITION" 1 "VELOCITY" 0 "IDLE" ;
VAL_ 2163278200 SubCode 34 "POWER" 33 "THOR" 32 "SAFETY" 31 "ECAT_ERR" 30 "BUZZER_CFG" 27 "ANGLE_MULTI" 26 "BAT_LATCH" 25 "SAFETY_SENSOR" 22 "HRMC" 19 "TOF" 18 "USS" 17 "ANGLE" 9 "TACTILE_G2" 5 "PING" ;
VAL_ 2147614976 EvtCode 19 "CAN_ID_CHANGED" 18 "THOR_OFF" 17 "ROBOT_OFF" 16 "BLACKBOX_TRIG" 15 "BAT_WARN" 14 "ESTOP_UPDATE" 13 "ERR_CLEAR" 12 "ERR_CODE" 11 "WIZ_PHY_SNTP" 10 "WIZ_PHY_DHCP" 9 "WIZ_PHY_LINK" 8 "PAUSE" 7 "ECAT_CONNECT" 6 "ANGLE_EX_CONNECT" 5 "BRAKE_EX_CONNECT" 4 "BLDC_FAULT" 3 "BLDC_TORQUE" 2 "BLDC_LIMIT" 1 "ESTOP" 0 "OK" ;
VAL_ 2163280641 SubCode 34 "POWER" 33 "THOR" 32 "SAFETY" 31 "ECAT_ERR" 30 "BUZZER_CFG" 27 "ANGLE_MULTI" 26 "BAT_LATCH" 25 "SAFETY_SENSOR" 22 "HRMC" 19 "TOF" 18 "USS" 17 "ANGLE" 9 "TACTILE_G2" 5 "PING" ;
VAL_ 2163280760 SubCode 34 "POWER" 33 "THOR" 32 "SAFETY" 31 "ECAT_ERR" 30 "BUZZER_CFG" 27 "ANGLE_MULTI" 26 "BAT_LATCH" 25 "SAFETY_SENSOR" 22 "HRMC" 19 "TOF" 18 "USS" 17 "ANGLE" 9 "TACTILE_G2" 5 "PING" ;
VAL_ 2147710978 ReqState 240 "FAULT_RESET" 10 "QC" 9 "ESTOP" 8 "ERROR" 7 "ERR_OCCUR" 6 "PROC_OFF" 5 "RUN" 4 "TORQUE_ON" 3 "PROC_ON" 2 "READY" 1 "DISABLED" 0 "INIT" ;
VAL_ 2147710978 DesiredMode 5 "TORQUE" 4 "WHEEL" 3 "SIMPLE" 2 "POSITION" 1 "VELOCITY" 0 "IDLE" ;
VAL_ 2147746424 PresentState 10 "QC" 9 "ESTOP" 8 "ERROR" 7 "ERR_OCCUR" 6 "PROC_OFF" 5 "RUN" 4 "TORQUE_ON" 3 "PROC_ON" 2 "READY" 1 "DISABLED" 0 "INIT" ;
VAL_ 2147746424 PresentMode 5 "TORQUE" 4 "WHEEL" 3 "SIMPLE" 2 "POSITION" 1 "VELOCITY" 0 "IDLE" ;
VAL_ 2163278456 SubCode 34 "POWER" 33 "THOR" 32 "SAFETY" 31 "ECAT_ERR" 30 "BUZZER_CFG" 27 "ANGLE_MULTI" 26 "BAT_LATCH" 25 "SAFETY_SENSOR" 22 "HRMC" 19 "TOF" 18 "USS" 17 "ANGLE" 9 "TACTILE_G2" 5 "PING" ;
VAL_ 2147615232 EvtCode 19 "CAN_ID_CHANGED" 18 "THOR_OFF" 17 "ROBOT_OFF" 16 "BLACKBOX_TRIG" 15 "BAT_WARN" 14 "ESTOP_UPDATE" 13 "ERR_CLEAR" 12 "ERR_CODE" 11 "WIZ_PHY_SNTP" 10 "WIZ_PHY_DHCP" 9 "WIZ_PHY_LINK" 8 "PAUSE" 7 "ECAT_CONNECT" 6 "ANGLE_EX_CONNECT" 5 "BRAKE_EX_CONNECT" 4 "BLDC_FAULT" 3 "BLDC_TORQUE" 2 "BLDC_LIMIT" 1 "ESTOP" 0 "OK" ;
VAL_ 2163280898 SubCode 34 "POWER" 33 "THOR" 32 "SAFETY" 31 "ECAT_ERR" 30 "BUZZER_CFG" 27 "ANGLE_MULTI" 26 "BAT_LATCH" 25 "SAFETY_SENSOR" 22 "HRMC" 19 "TOF" 18 "USS" 17 "ANGLE" 9 "TACTILE_G2" 5 "PING" ;
VAL_ 2163281016 SubCode 34 "POWER" 33 "THOR" 32 "SAFETY" 31 "ECAT_ERR" 30 "BUZZER_CFG" 27 "ANGLE_MULTI" 26 "BAT_LATCH" 25 "SAFETY_SENSOR" 22 "HRMC" 19 "TOF" 18 "USS" 17 "ANGLE" 9 "TACTILE_G2" 5 "PING" ;
VAL_ 2147710979 ReqState 240 "FAULT_RESET" 10 "QC" 9 "ESTOP" 8 "ERROR" 7 "ERR_OCCUR" 6 "PROC_OFF" 5 "RUN" 4 "TORQUE_ON" 3 "PROC_ON" 2 "READY" 1 "DISABLED" 0 "INIT" ;
VAL_ 2147710979 DesiredMode 5 "TORQUE" 4 "WHEEL" 3 "SIMPLE" 2 "POSITION" 1 "VELOCITY" 0 "IDLE" ;
VAL_ 2147746680 PresentState 10 "QC" 9 "ESTOP" 8 "ERROR" 7 "ERR_OCCUR" 6 "PROC_OFF" 5 "RUN" 4 "TORQUE_ON" 3 "PROC_ON" 2 "READY" 1 "DISABLED" 0 "INIT" ;
VAL_ 2147746680 PresentMode 5 "TORQUE" 4 "WHEEL" 3 "SIMPLE" 2 "POSITION" 1 "VELOCITY" 0 "IDLE" ;
VAL_ 2163278712 SubCode 34 "POWER" 33 "THOR" 32 "SAFETY" 31 "ECAT_ERR" 30 "BUZZER_CFG" 27 "ANGLE_MULTI" 26 "BAT_LATCH" 25 "SAFETY_SENSOR" 22 "HRMC" 19 "TOF" 18 "USS" 17 "ANGLE" 9 "TACTILE_G2" 5 "PING" ;
VAL_ 2147615488 EvtCode 19 "CAN_ID_CHANGED" 18 "THOR_OFF" 17 "ROBOT_OFF" 16 "BLACKBOX_TRIG" 15 "BAT_WARN" 14 "ESTOP_UPDATE" 13 "ERR_CLEAR" 12 "ERR_CODE" 11 "WIZ_PHY_SNTP" 10 "WIZ_PHY_DHCP" 9 "WIZ_PHY_LINK" 8 "PAUSE" 7 "ECAT_CONNECT" 6 "ANGLE_EX_CONNECT" 5 "BRAKE_EX_CONNECT" 4 "BLDC_FAULT" 3 "BLDC_TORQUE" 2 "BLDC_LIMIT" 1 "ESTOP" 0 "OK" ;
VAL_ 2163281155 SubCode 34 "POWER" 33 "THOR" 32 "SAFETY" 31 "ECAT_ERR" 30 "BUZZER_CFG" 27 "ANGLE_MULTI" 26 "BAT_LATCH" 25 "SAFETY_SENSOR" 22 "HRMC" 19 "TOF" 18 "USS" 17 "ANGLE" 9 "TACTILE_G2" 5 "PING" ;
VAL_ 2163281272 SubCode 34 "POWER" 33 "THOR" 32 "SAFETY" 31 "ECAT_ERR" 30 "BUZZER_CFG" 27 "ANGLE_MULTI" 26 "BAT_LATCH" 25 "SAFETY_SENSOR" 22 "HRMC" 19 "TOF" 18 "USS" 17 "ANGLE" 9 "TACTILE_G2" 5 "PING" ;
VAL_ 2147710980 ReqState 240 "FAULT_RESET" 10 "QC" 9 "ESTOP" 8 "ERROR" 7 "ERR_OCCUR" 6 "PROC_OFF" 5 "RUN" 4 "TORQUE_ON" 3 "PROC_ON" 2 "READY" 1 "DISABLED" 0 "INIT" ;
VAL_ 2147710980 DesiredMode 5 "TORQUE" 4 "WHEEL" 3 "SIMPLE" 2 "POSITION" 1 "VELOCITY" 0 "IDLE" ;
VAL_ 2147746936 PresentState 10 "QC" 9 "ESTOP" 8 "ERROR" 7 "ERR_OCCUR" 6 "PROC_OFF" 5 "RUN" 4 "TORQUE_ON" 3 "PROC_ON" 2 "READY" 1 "DISABLED" 0 "INIT" ;
VAL_ 2147746936 PresentMode 5 "TORQUE" 4 "WHEEL" 3 "SIMPLE" 2 "POSITION" 1 "VELOCITY" 0 "IDLE" ;
VAL_ 2163278968 SubCode 34 "POWER" 33 "THOR" 32 "SAFETY" 31 "ECAT_ERR" 30 "BUZZER_CFG" 27 "ANGLE_MULTI" 26 "BAT_LATCH" 25 "SAFETY_SENSOR" 22 "HRMC" 19 "TOF" 18 "USS" 17 "ANGLE" 9 "TACTILE_G2" 5 "PING" ;
VAL_ 2147615744 EvtCode 19 "CAN_ID_CHANGED" 18 "THOR_OFF" 17 "ROBOT_OFF" 16 "BLACKBOX_TRIG" 15 "BAT_WARN" 14 "ESTOP_UPDATE" 13 "ERR_CLEAR" 12 "ERR_CODE" 11 "WIZ_PHY_SNTP" 10 "WIZ_PHY_DHCP" 9 "WIZ_PHY_LINK" 8 "PAUSE" 7 "ECAT_CONNECT" 6 "ANGLE_EX_CONNECT" 5 "BRAKE_EX_CONNECT" 4 "BLDC_FAULT" 3 "BLDC_TORQUE" 2 "BLDC_LIMIT" 1 "ESTOP" 0 "OK" ;
VAL_ 2163281412 SubCode 34 "POWER" 33 "THOR" 32 "SAFETY" 31 "ECAT_ERR" 30 "BUZZER_CFG" 27 "ANGLE_MULTI" 26 "BAT_LATCH" 25 "SAFETY_SENSOR" 22 "HRMC" 19 "TOF" 18 "USS" 17 "ANGLE" 9 "TACTILE_G2" 5 "PING" ;
VAL_ 2163281528 SubCode 34 "POWER" 33 "THOR" 32 "SAFETY" 31 "ECAT_ERR" 30 "BUZZER_CFG" 27 "ANGLE_MULTI" 26 "BAT_LATCH" 25 "SAFETY_SENSOR" 22 "HRMC" 19 "TOF" 18 "USS" 17 "ANGLE" 9 "TACTILE_G2" 5 "PING" ;
VAL_ 2147710981 ReqState 240 "FAULT_RESET" 10 "QC" 9 "ESTOP" 8 "ERROR" 7 "ERR_OCCUR" 6 "PROC_OFF" 5 "RUN" 4 "TORQUE_ON" 3 "PROC_ON" 2 "READY" 1 "DISABLED" 0 "INIT" ;
VAL_ 2147710981 DesiredMode 5 "TORQUE" 4 "WHEEL" 3 "SIMPLE" 2 "POSITION" 1 "VELOCITY" 0 "IDLE" ;
VAL_ 2147747192 PresentState 10 "QC" 9 "ESTOP" 8 "ERROR" 7 "ERR_OCCUR" 6 "PROC_OFF" 5 "RUN" 4 "TORQUE_ON" 3 "PROC_ON" 2 "READY" 1 "DISABLED" 0 "INIT" ;
VAL_ 2147747192 PresentMode 5 "TORQUE" 4 "WHEEL" 3 "SIMPLE" 2 "POSITION" 1 "VELOCITY" 0 "IDLE" ;
VAL_ 2163279224 SubCode 34 "POWER" 33 "THOR" 32 "SAFETY" 31 "ECAT_ERR" 30 "BUZZER_CFG" 27 "ANGLE_MULTI" 26 "BAT_LATCH" 25 "SAFETY_SENSOR" 22 "HRMC" 19 "TOF" 18 "USS" 17 "ANGLE" 9 "TACTILE_G2" 5 "PING" ;
VAL_ 2147616000 EvtCode 19 "CAN_ID_CHANGED" 18 "THOR_OFF" 17 "ROBOT_OFF" 16 "BLACKBOX_TRIG" 15 "BAT_WARN" 14 "ESTOP_UPDATE" 13 "ERR_CLEAR" 12 "ERR_CODE" 11 "WIZ_PHY_SNTP" 10 "WIZ_PHY_DHCP" 9 "WIZ_PHY_LINK" 8 "PAUSE" 7 "ECAT_CONNECT" 6 "ANGLE_EX_CONNECT" 5 "BRAKE_EX_CONNECT" 4 "BLDC_FAULT" 3 "BLDC_TORQUE" 2 "BLDC_LIMIT" 1 "ESTOP" 0 "OK" ;
VAL_ 2163281669 SubCode 34 "POWER" 33 "THOR" 32 "SAFETY" 31 "ECAT_ERR" 30 "BUZZER_CFG" 27 "ANGLE_MULTI" 26 "BAT_LATCH" 25 "SAFETY_SENSOR" 22 "HRMC" 19 "TOF" 18 "USS" 17 "ANGLE" 9 "TACTILE_G2" 5 "PING" ;
VAL_ 2163281784 SubCode 34 "POWER" 33 "THOR" 32 "SAFETY" 31 "ECAT_ERR" 30 "BUZZER_CFG" 27 "ANGLE_MULTI" 26 "BAT_LATCH" 25 "SAFETY_SENSOR" 22 "HRMC" 19 "TOF" 18 "USS" 17 "ANGLE" 9 "TACTILE_G2" 5 "PING" ;
SIG_VALTYPE_ 2147710977 DesiredPosition : 1;
SIG_VALTYPE_ 2147710977 DesiredVelocity : 1;
SIG_VALTYPE_ 2147710977 DesiredTorque : 1;
SIG_VALTYPE_ 2147746168 PresentPosition : 1;
SIG_VALTYPE_ 2147746168 PresentVelocity : 1;
SIG_VALTYPE_ 2147746168 PresentTorque : 1;
SIG_VALTYPE_ 2163280641 Ang_AngleRad : 1;
SIG_VALTYPE_ 2147710978 DesiredPosition : 1;
SIG_VALTYPE_ 2147710978 DesiredVelocity : 1;
SIG_VALTYPE_ 2147710978 DesiredTorque : 1;
SIG_VALTYPE_ 2147746424 PresentPosition : 1;
SIG_VALTYPE_ 2147746424 PresentVelocity : 1;
SIG_VALTYPE_ 2147746424 PresentTorque : 1;
SIG_VALTYPE_ 2163280898 Ang_AngleRad : 1;
SIG_VALTYPE_ 2147710979 DesiredPosition : 1;
SIG_VALTYPE_ 2147710979 DesiredVelocity : 1;
SIG_VALTYPE_ 2147710979 DesiredTorque : 1;
SIG_VALTYPE_ 2147746680 PresentPosition : 1;
SIG_VALTYPE_ 2147746680 PresentVelocity : 1;
SIG_VALTYPE_ 2147746680 PresentTorque : 1;
SIG_VALTYPE_ 2163281155 Ang_AngleRad : 1;
SIG_VALTYPE_ 2147710980 DesiredPosition : 1;
SIG_VALTYPE_ 2147710980 DesiredVelocity : 1;
SIG_VALTYPE_ 2147710980 DesiredTorque : 1;
SIG_VALTYPE_ 2147746936 PresentPosition : 1;
SIG_VALTYPE_ 2147746936 PresentVelocity : 1;
SIG_VALTYPE_ 2147746936 PresentTorque : 1;
SIG_VALTYPE_ 2163281412 Ang_AngleRad : 1;
SIG_VALTYPE_ 2147710981 DesiredPosition : 1;
SIG_VALTYPE_ 2147710981 DesiredVelocity : 1;
SIG_VALTYPE_ 2147710981 DesiredTorque : 1;
SIG_VALTYPE_ 2147747192 PresentPosition : 1;
SIG_VALTYPE_ 2147747192 PresentVelocity : 1;
SIG_VALTYPE_ 2147747192 PresentTorque : 1;
SIG_VALTYPE_ 2163281669 Ang_AngleRad : 1;
